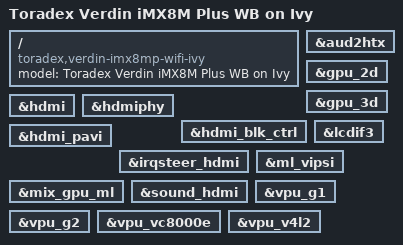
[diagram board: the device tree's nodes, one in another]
// SPDX-License-Identifier: GPL-2.0-or-later OR MIT
/*
 * Copyright 2024 Toradex
 * Copyright 2025 MicroHobby
 */

/dts-v1/;

#include "imx8mp-verdin.dtsi"
#include "imx8mp-verdin-wifi.dtsi"
#include "imx8mp-verdin-ivy.dtsi"

/ {
	model = "Toradex Verdin iMX8M Plus WB on Ivy";
	compatible = "toradex,verdin-imx8mp-wifi-ivy",
		     "toradex,verdin-imx8mp-wifi",
		     "toradex,verdin-imx8mp",
		     "fsl,imx8mp";
};

&aud2htx {
	status = "okay";
};

&gpu_2d {
	status = "okay";
};

&gpu_3d {
	status = "okay";
};

&hdmi {
	status = "okay";
};

&hdmiphy {
	status = "okay";
};

&hdmi_blk_ctrl {
	status = "okay";
};

&hdmi_pavi {
	status = "okay";
};

&irqsteer_hdmi {
	status = "okay";
};

/* LCDIF to on-SoC Samsung HDMI PHY */
&lcdif3 {
	status = "okay";
};

&ml_vipsi {
	status = "okay";
};

&mix_gpu_ml {
	status = "okay";
};

&sound_hdmi {
	status = "okay";
};

&vpu_g1 {
	status = "okay";
};

&vpu_g2 {
	status = "okay";
};

&vpu_vc8000e {
	status = "okay";
};

&vpu_v4l2 {
	status = "okay";
};
